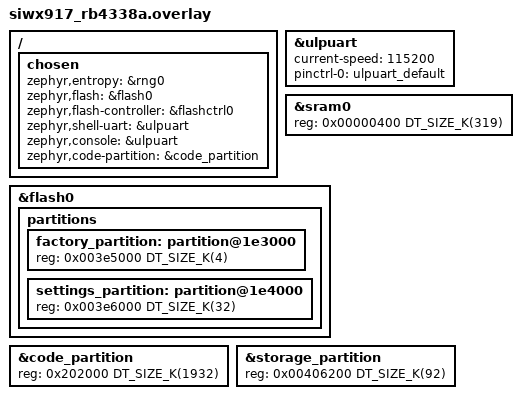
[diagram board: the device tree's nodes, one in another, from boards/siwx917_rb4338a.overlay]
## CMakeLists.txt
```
#
# Copyright (c) 2025 Project CHIP Authors
#
# Licensed under the Apache License, Version 2.0 (the "License");
# you may not use this file except in compliance with the License.
# You may obtain a copy of the License at
#
# http://www.apache.org/licenses/LICENSE-2.0
#
# Unless required by applicable law or agreed to in writing, software
# distributed under the License is distributed on an "AS IS" BASIS,
# WITHOUT WARRANTIES OR CONDITIONS OF ANY KIND, either express or implied.
# See the License for the specific language governing permissions and
# limitations under the License.
#
cmake_minimum_required(VERSION 3.20)

get_filename_component(CHIP_ROOT ${CMAKE_CURRENT_SOURCE_DIR}/../third_party/connectedhomeip REALPATH)
get_filename_component(GEN_DIR ${CHIP_ROOT}/zzz_generated/ REALPATH)
get_filename_component(ZEPHYR_PLATFORM_COMMON ${CHIP_ROOT}/examples/platform/silabs/zephyr REALPATH)
get_filename_component(SILABS_LIGHTING_COMMON ${CHIP_ROOT}/examples/lighting-app/silabs REALPATH)
get_filename_component(ALL_CLUSTERS_COMMON_DIR ${CHIP_ROOT}/examples/all-clusters-app/all-clusters-common REALPATH)


# Need this as wiseconnect abstraction is causing a build failure
add_definitions(-DMBEDTLS_X509_REMOVE_INFO )

list(APPEND ZEPHYR_EXTRA_MODULES ${CHIP_ROOT}/config/silabs)
find_package(Zephyr HINTS $ENV{ZEPHYR_BASE})

if(CONFIG_OPENTHREAD AND TARGET ot-config AND TARGET zephyr_interface)
    get_target_property(OT_CONFIG_DEFS ot-config INTERFACE_COMPILE_DEFINITIONS)
    if(OT_CONFIG_DEFS)
        list(FILTER OT_CONFIG_DEFS EXCLUDE REGEX "TARGET_PROPERTY:zephyr_interface,INTERFACE_COMPILE_DEFINITIONS")
    else()
        set(OT_CONFIG_DEFS "")
    endif()
    get_target_property(ZEPHYR_INTERFACE_DEFS zephyr_interface INTERFACE_COMPILE_DEFINITIONS)
    if(ZEPHYR_INTERFACE_DEFS)
        list(FILTER ZEPHYR_INTERFACE_DEFS EXCLUDE REGEX "COMPILE_LANGUAGE:CXX")
    else()
        set(ZEPHYR_INTERFACE_DEFS "")
    endif()
    set_target_properties(ot-config PROPERTIES
        INTERFACE_COMPILE_DEFINITIONS "${OT_CONFIG_DEFS};${ZEPHYR_INTERFACE_DEFS}")
endif()

if(CMAKE_C_COMPILER_ID STREQUAL "Clang")
    foreach(_mbedtls_lib mbedtls mbedx509 tfpsacrypto builtin p256-m pqcp extras platform utilities)
        if(TARGET ${_mbedtls_lib})
            target_compile_options(${_mbedtls_lib} PRIVATE -Wno-documentation -Wno-c99-extensions)
        endif()
    endforeach()
    
    if(CONFIG_OPENTHREAD)
        foreach(_ot_lib openthread-ftd openthread-mtd openthread-radio openthread-cli-ftd openthread-cli-mtd)
            if(TARGET ${_ot_lib})
                target_compile_options(${_ot_lib} PRIVATE -Wno-c99-extensions)
            endif()
        endforeach()
    endif()
endif()

# -Wmaybe-uninitialized has too many false positives, including on std::optional
# and chip::Optional.  Make it nonfatal.
#
# See https://gcc.gnu.org/bugzilla/show_bug.cgi?id=80635
target_compile_options(app PRIVATE -Werror -Wno-error=format)
if(CMAKE_C_COMPILER_ID STREQUAL "GNU")
    target_compile_options(app PRIVATE -Werror -Wno-error=maybe-uninitialized)
endif()

project(matter-zephyr-light)

include(${CHIP_ROOT}/config/silabs/app/enable-gnu-std.cmake)
include(${CHIP_ROOT}/src/app/chip_data_model.cmake)

target_include_directories(app
    PRIVATE
    include
    ${ZEPHYR_PLATFORM_COMMON}
)

target_sources(app
    PRIVATE
    src/AppTask.cpp
    src/DeviceCallbacks.cpp
    ../include/CHIPProjectConfig.h
    ${ZEPHYR_PLATFORM_COMMON}/main.cpp
    ${ZEPHYR_PLATFORM_COMMON}/AppTaskBase.cpp
    ${ZEPHYR_PLATFORM_COMMON}/AppTaskZephyr.cpp
    ${ZEPHYR_PLATFORM_COMMON}/CHIPDeviceManager.cpp
    ${ZEPHYR_PLATFORM_COMMON}/CommonDeviceCallbacks.cpp
    ${ZEPHYR_PLATFORM_COMMON}/DataModelCallbacks.cpp
)

if(CONFIG_CHIP_FACTORY_DATA)
    target_sources(app PRIVATE
                    ${CHIP_ROOT}/examples/platform/silabs/provision/ProvisionStorageReaderCommon.cpp
                    ${CHIP_ROOT}/examples/platform/silabs/provision/zephyr/ProvisionStorageReader.cpp
    )
    target_include_directories(app PRIVATE
                    ${CHIP_ROOT}/examples/platform/silabs
                    ${CHIP_ROOT}/third_party/silabs/matter_support/provision
    )
    target_compile_definitions(app PRIVATE
        SL_PROVISION_GENERATOR=0
    )
endif()

if(CONFIG_CHIP_OTA_REQUESTOR)
    target_sources(app PRIVATE
                    ${ZEPHYR_PLATFORM_COMMON}/ota_requestor/source/OTARequestorInitiatorCommon.cpp
                    ${ZEPHYR_PLATFORM_COMMON}/ota_requestor/source/OTARequestorInitiatorZephyr.cpp
    )
    target_include_directories(app PRIVATE
                    ${ZEPHYR_PLATFORM_COMMON}/ota_requestor/include/
    )
endif()

if(CONFIG_CHIP_WIFI)
  chip_configure_data_model(app INCLUDE_SERVER
      ZAP_FILE ${SILABS_LIGHTING_COMMON}/data_model/lighting-wifi-app.zap
  )
else()
  chip_configure_data_model(app INCLUDE_SERVER
      ZAP_FILE ${SILABS_LIGHTING_COMMON}/data_model/lighting-thread-app.zap
  )
endif()

if(CONFIG_CHIP_LIB_SHELL)
    target_compile_definitions(app PRIVATE ENABLE_CHIP_SHELL)
    target_include_directories(app PRIVATE 
                               ${CHIP_ROOT}/examples/shell/shell_common/include
                               ${ZEPHYR_PLATFORM_COMMON}/include
    )
    target_sources(app PRIVATE
                   ${ZEPHYR_PLATFORM_COMMON}/AppCLIZephyr.cpp
                   ${CHIP_ROOT}/examples/shell/shell_common/cmd_misc.cpp
                   ${CHIP_ROOT}/examples/shell/shell_common/cmd_otcli.cpp
                   ${CHIP_ROOT}/examples/shell/shell_common/cmd_server.cpp
    )
endif()

include(${CHIP_ROOT}/config/silabs/app/zephyr-post-build.cmake)
```

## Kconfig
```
#
#    Copyright (c) 2025 Project CHIP Authors
#
#    Licensed under the Apache License, Version 2.0 (the "License");
#    you may not use this file except in compliance with the License.
#    You may obtain a copy of the License at
#
#        http://www.apache.org/licenses/LICENSE-2.0
#
#    Unless required by applicable law or agreed to in writing, software
#    distributed under the License is distributed on an "AS IS" BASIS,
#    WITHOUT WARRANTIES OR CONDITIONS OF ANY KIND, either express or implied.
#    See the License for the specific language governing permissions and
#    limitations under the License.
#
mainmenu "Matter Silabs Lighting Example Application"

# Sample configuration used for Thread networking
if NET_L2_OPENTHREAD
choice OPENTHREAD_DEVICE_TYPE
	default OPENTHREAD_FTD
endchoice
endif # NET_L2_OPENTHREAD

rsource "../../../../config/silabs/Kconfig.defaults"
rsource "../../../../config/silabs/Kconfig"
source "Kconfig.zephyr"
```

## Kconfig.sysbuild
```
#
#    Copyright (c) 2026 Project CHIP Authors
#
#    Licensed under the Apache License, Version 2.0 (the "License");
#    you may not use this file except in compliance with the License.
#    You may obtain a copy of the License at
#
#        http://www.apache.org/licenses/LICENSE-2.0
#
#    Unless required by applicable law or agreed to in writing, software
#    distributed under the License is distributed on an "AS IS" BASIS,
#    WITHOUT WARRANTIES OR CONDITIONS OF ANY KIND, either express or implied.
#    See the License for the specific language governing permissions and
#    limitations under the License.
#

source "${ZEPHYR_BASE}/share/sysbuild/Kconfig"

# Silabs Matter OTA images use overwrite-only MCUboot

if BOOTLOADER_MCUBOOT

choice MCUBOOT_MODE
	default MCUBOOT_MODE_OVERWRITE_ONLY
endchoice

choice BOOT_SIGNATURE_TYPE
	default BOOT_SIGNATURE_TYPE_ECDSA_P256
endchoice

endif # BOOTLOADER_MCUBOOT
```

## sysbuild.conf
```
#
#    Copyright (c) 2026 Project CHIP Authors
#
#    Licensed under the Apache License, Version 2.0 (the "License");
#    you may not use this file except in compliance with the License.
#    You may obtain a copy of the License at
#
#        http://www.apache.org/licenses/LICENSE-2.0
#
#    Unless required by applicable law or agreed to in writing, software
#    distributed under the License is distributed on an "AS IS" BASIS,
#    WITHOUT WARRANTIES OR CONDITIONS OF ANY KIND, either express or implied.
#    See the License for the specific language governing permissions and
#    limitations under the License.
#

SB_CONFIG_MERGED_HEX_FILES=y

SB_CONFIG_MCUBOOT_MODE_OVERWRITE_ONLY=y
SB_CONFIG_BOOT_SIGNATURE_TYPE_ECDSA_P256=y
```

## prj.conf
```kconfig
#
#    Copyright (c) 2025 Project CHIP Authors
#
#    Licensed under the Apache License, Version 2.0 (the "License");
#    you may not use this file except in compliance with the License.
#    You may obtain a copy of the License at
#
#        http://www.apache.org/licenses/LICENSE-2.0
#
#    Unless required by applicable law or agreed to in writing, software
#    distributed under the License is distributed on an "AS IS" BASIS,
#    WITHOUT WARRANTIES OR CONDITIONS OF ANY KIND, either express or implied.
#    See the License for the specific language governing permissions and
#    limitations under the License.
#

# This sample uses Kconfig.defaults to set options common for all
# samples. This file should contain only options specific for this sample
# or overrides of default values.

# Main subsystems
CONFIG_CHIP=y
CONFIG_GPIO=y

# Chip related options
CONFIG_CHIP_PROJECT_CONFIG="../include/CHIPProjectConfig.h"
# 32773 == 0x8005 (example lighting-app)
CONFIG_CHIP_DEVICE_PRODUCT_ID=32773
CONFIG_CHIP_ENABLE_PAIRING_AUTOSTART=y
CONFIG_CHIP_BLE_EXT_ADVERTISING=y
CONFIG_CHIP_BLE_ADVERTISING_DURATION=60
CONFIG_BT_DEVICE_NAME="MatterLight"
CONFIG_NET_IF_MCAST_IPV6_ADDR_COUNT=5
CONFIG_SETTINGS_NVS_SECTOR_COUNT=6
CONFIG_STD_CPP17=y
# Workaround for undefined reference to `bt_rand'
CONFIG_BT_HOST_CRYPTO=y

CONFIG_LOG_MODE_MINIMAL=n
CONFIG_LOG_MODE_DEFERRED=y
CONFIG_LOG_BUFFER_SIZE=8192
CONFIG_LOG_DEFAULT_LEVEL=3

CONFIG_MBEDTLS_HEAP_SIZE=16384

# Shell commands
CONFIG_CHIP_LIB_SHELL=y

# Stack sizes
CONFIG_SYSTEM_WORKQUEUE_STACK_SIZE=4096
CONFIG_MAIN_STACK_SIZE=8192
CONFIG_SHELL_STACK_SIZE=4096
```

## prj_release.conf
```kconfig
#
#    Copyright (c) 2025 Project CHIP Authors
#
#    Licensed under the Apache License, Version 2.0 (the "License");
#    you may not use this file except in compliance with the License.
#    You may obtain a copy of the License at
#
#        http://www.apache.org/licenses/LICENSE-2.0
#
#    Unless required by applicable law or agreed to in writing, software
#    distributed under the License is distributed on an "AS IS" BASIS,
#    WITHOUT WARRANTIES OR CONDITIONS OF ANY KIND, either express or implied.
#    See the License for the specific language governing permissions and
#    limitations under the License.
#

# This sample uses Kconfig.defaults to set options common for all
# samples. This file should contain only options specific for this sample
# or overrides of default values.

# Enable CHIP
CONFIG_CHIP=y
CONFIG_CHIP_PROJECT_CONFIG="../include/CHIPProjectConfig.h"
# 32773 == 0x8005 (example lighting-app)
CONFIG_CHIP_DEVICE_PRODUCT_ID=32773
CONFIG_STD_CPP17=y

# Enable Matter pairing automatically on application start.
CONFIG_CHIP_ENABLE_PAIRING_AUTOSTART=y

# Enable Matter extended announcement and increase duration to 1 hour.
CONFIG_CHIP_BLE_EXT_ADVERTISING=y
CONFIG_CHIP_BLE_ADVERTISING_DURATION=60

# General networking settings
CONFIG_NET_IF_MCAST_IPV6_ADDR_COUNT=14

# Bluetooth Low Energy configuration
CONFIG_BT_DEVICE_NAME="MatterLight"

# Disable all debug features
CONFIG_USE_SEGGER_RTT=n
CONFIG_SHELL=n
CONFIG_OPENTHREAD_SHELL=n
CONFIG_CONSOLE=n
CONFIG_UART_CONSOLE=n
CONFIG_SERIAL=n
CONFIG_LOG=n
CONFIG_LOG_MODE_MINIMAL=n
CONFIG_ASSERT_VERBOSE=n
CONFIG_ASSERT_NO_FILE_INFO=y
CONFIG_PRINTK=n
CONFIG_PRINTK_SYNC=n
CONFIG_BOOT_BANNER=n
```

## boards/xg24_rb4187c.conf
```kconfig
#
#    Copyright (c) 2026 Project CHIP Authors
#    All rights reserved.
#
#    Licensed under the Apache License, Version 2.0 (the "License");
#    you may not use this file except in compliance with the License.
#    You may obtain a copy of the License at
#
#        http://www.apache.org/licenses/LICENSE-2.0
#
#    Unless required by applicable law or agreed to in writing, software
#    distributed under the License is distributed on an "AS IS" BASIS,
#    WITHOUT WARRANTIES OR CONDITIONS OF ANY KIND, either express or implied.
#    See the License for the specific language governing permissions and
#    limitations under the License.
#


# Drivers required to read/write the external SPI NOR;
# Enables external flash for OTA support
CONFIG_SPI=y
CONFIG_SPI_SILABS_EUSART=y
CONFIG_SPI_NOR=y

# Bootloader overwrite-only mode for computing image padding/overflow.
CONFIG_MCUBOOT_IMGTOOL_OVERWRITE_ONLY=y
CONFIG_MCUBOOT_BOOTLOADER_MODE_OVERWRITE_ONLY=y
```

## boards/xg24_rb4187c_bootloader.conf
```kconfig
#
#    Copyright (c) 2026 Project CHIP Authors
#    All rights reserved.
#
#    Licensed under the Apache License, Version 2.0 (the "License");
#    you may not use this file except in compliance with the License.
#    You may obtain a copy of the License at
#
#        http://www.apache.org/licenses/LICENSE-2.0
#
#    Unless required by applicable law or agreed to in writing, software
#    distributed under the License is distributed on an "AS IS" BASIS,
#    WITHOUT WARRANTIES OR CONDITIONS OF ANY KIND, either express or implied.
#    See the License for the specific language governing permissions and
#    limitations under the License.
#

# Overwrite-only install: the secondary slot (slot1) lives on the external SPI
# NOR and the primary (slot0) on internal flash, so the slots cannot be swapped
CONFIG_BOOT_UPGRADE_ONLY=y

# Drivers required to read/write the external SPI NOR;
# Enables external flash for OTA support
CONFIG_SPI=y
CONFIG_SPI_SILABS_EUSART=y
CONFIG_SPI_NOR=y
```

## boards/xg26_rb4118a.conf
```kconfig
#
#    Copyright (c) 2026 Project CHIP Authors
#    All rights reserved.
#
#    Licensed under the Apache License, Version 2.0 (the "License");
#    you may not use this file except in compliance with the License.
#    You may obtain a copy of the License at
#
#        http://www.apache.org/licenses/LICENSE-2.0
#
#    Unless required by applicable law or agreed to in writing, software
#    distributed under the License is distributed on an "AS IS" BASIS,
#    WITHOUT WARRANTIES OR CONDITIONS OF ANY KIND, either express or implied.
#    See the License for the specific language governing permissions and
#    limitations under the License.
#

# Bootloader overwrite-only mode for computing image padding/overflow.
CONFIG_MCUBOOT_IMGTOOL_OVERWRITE_ONLY=y
CONFIG_MCUBOOT_BOOTLOADER_MODE_OVERWRITE_ONLY=y
```

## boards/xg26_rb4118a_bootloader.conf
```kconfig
#
#    Copyright (c) 2026 Project CHIP Authors
#    All rights reserved.
#
#    Licensed under the Apache License, Version 2.0 (the "License");
#    you may not use this file except in compliance with the License.
#    You may obtain a copy of the License at
#
#        http://www.apache.org/licenses/LICENSE-2.0
#
#    Unless required by applicable law or agreed to in writing, software
#    distributed under the License is distributed on an "AS IS" BASIS,
#    WITHOUT WARRANTIES OR CONDITIONS OF ANY KIND, either express or implied.
#    See the License for the specific language governing permissions and
#    limitations under the License.
#

CONFIG_BOOT_UPGRADE_ONLY=y
```

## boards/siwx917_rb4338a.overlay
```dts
/*
 *    Copyright (c) 2025 Project CHIP Authors
 *    All rights reserved.
 *
 *    Licensed under the Apache License, Version 2.0 (the "License");
 *    you may not use this file except in compliance with the License.
 *    You may obtain a copy of the License at
 *
 *        http://www.apache.org/licenses/LICENSE-2.0
 *
 *    Unless required by applicable law or agreed to in writing, software
 *    distributed under the License is distributed on an "AS IS" BASIS
 *    WITHOUT WARRANTIES OR CONDITIONS OF ANY KIND, either express or implied.
 *    See the License for the specific language governing permissions and
 *    limitations under the License.
 */

/ {
	chosen {
		zephyr,entropy = &rng0;
		zephyr,flash = &flash0;
		zephyr,flash-controller = &flashctrl0;
		zephyr,shell-uart = &ulpuart;
		zephyr,console = &ulpuart;
		zephyr,code-partition = &code_partition;
	};
};

&ulpuart {
	status = "okay";
	current-speed = <115200>;
	pinctrl-0 = <&ulpuart_default>;
	pinctrl-names = "default";
};



&sram0 {
    status = "okay";
    reg = <0x00000400 DT_SIZE_K(319)>;
};

&flash0 {
        partitions {
                factory_partition: partition@1e3000 {
                        reg = <0x003e5000 DT_SIZE_K(4)>;
                };

                settings_partition: partition@1e4000 {
                        reg = <0x003e6000 DT_SIZE_K(32)>;
                };
        };
};

&code_partition {
       reg = <0x202000 DT_SIZE_K(1932)>;
};


&storage_partition {
        reg = <0x00406200 DT_SIZE_K(92)>;
};
```

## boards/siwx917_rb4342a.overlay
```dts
/*
 * Copyright (c) 2025 Project CHIP Authors
 *
 * Licensed under the Apache License, Version 2.0 (the "License");
 * you may not use this file except in compliance with the License.
 * You may obtain a copy of the License at
 *
 *     http://www.apache.org/licenses/LICENSE-2.0
 *
 * Unless required by applicable law or agreed to in writing, software
 * distributed under the License is distributed on an "AS IS" BASIS
 * WITHOUT WARRANTIES OR CONDITIONS OF ANY KIND, either express or implied.
 * See the License for the specific language governing permissions and
 * limitations under the License.
 */

&flash0 {
	partitions {
		/*
		 * M4 free space ends at 0x400000 (start of SoC ota_swap_partition).
		 * code (1912) + factory (4) + settings (32) + storage (92) = 2040 KiB.
		 * Do not place app NVM inside ota_swap — that region is owned by the
		 * NWP/Security Bootloader for RPS firmware upgrade.
		 */
		factory_partition: partition@3e0000 {
			reg = <0x003e0000 DT_SIZE_K(4)>;
		};

		settings_partition: partition@3e1000 {
			reg = <0x003e1000 DT_SIZE_K(32)>;
		};
	};
};

&code_partition {
	reg = <0x00202000 DT_SIZE_K(1912)>;
};

&storage_partition {
	reg = <0x003e9000 DT_SIZE_K(92)>;
};
```

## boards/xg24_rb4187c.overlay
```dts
/*
 *	Copyright (c) 2026 Project CHIP Authors
 *	All rights reserved.
 *
 *	Licensed under the Apache License, Version 2.0 (the "License");
 *	you may not use this file except in compliance with the License.
 *	You may obtain a copy of the License at
 *
 *	    http://www.apache.org/licenses/LICENSE-2.0
 *
 *	Unless required by applicable law or agreed to in writing, software
 *	distributed under the License is distributed on an "AS IS" BASIS
 *	WITHOUT WARRANTIES OR CONDITIONS OF ANY KIND, either express or implied.
 *	See the License for the specific language governing permissions and
 *	limitations under the License.
 */

/*
 * Internal flash (1536 KiB): boot (48) + slot0 (1024) + unused (416) + storage (48).
 * slot1 matches slot0 size on the external MX25R80.
 * slot0/slot1 must match for MCUboot in overwrite-only mode.
 */
/delete-node/ &slot0_partition;
/delete-node/ &slot1_partition;
/delete-node/ &storage_partition;

&flash0 {
	partitions {
		slot0_partition: partition@c000 {
			reg = <0x0000c000 DT_SIZE_K(1024)>;
			label = "image-0";
		};

		unused_partition: partition@10c000 {
			reg = <0x0010c000 DT_SIZE_K(416)>;
			label = "unused";
		};

		storage_partition: partition@174000 {
			reg = <0x00174000 DT_SIZE_K(48)>;
			label = "storage";
		};
	};
};

&mx25r80 {
	partitions {
		compatible = "fixed-partitions";
		#address-cells = <1>;
		#size-cells = <1>;

		slot1_partition: partition@0 {
			reg = <0x00000000 DT_SIZE_K(1024)>;
			label = "image-1";
		};
	};
};

&dma0 {
	status = "okay";
};

&usart0 {
	dmas = <&dma0 DMA_REQSEL_USART0TXBL>,
		   <&dma0 DMA_REQSEL_USART0RXDATAV>;
	dma-names = "tx", "rx";
};
```

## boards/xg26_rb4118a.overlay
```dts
/*
 *	Copyright (c) 2026 Project CHIP Authors
 *	All rights reserved.
 *
 *	Licensed under the Apache License, Version 2.0 (the "License");
 *	you may not use this file except in compliance with the License.
 *	You may obtain a copy of the License at
 *
 *		http://www.apache.org/licenses/LICENSE-2.0
 *
 *	Unless required by applicable law or agreed to in writing, software
 *	distributed under the License is distributed on an "AS IS" BASIS
 *	WITHOUT WARRANTIES OR CONDITIONS OF ANY KIND, either express or implied.
 *	See the License for the specific language governing permissions and
 *	limitations under the License.
 */

/*
 * Internal flash (3200 KiB): boot (48) + slot0 (1552) + slot1 (1552) + storage (48).
 */
/delete-node/ &slot0_partition;
/delete-node/ &slot1_partition;
/delete-node/ &storage_partition;

&flash0 {
	partitions {
		slot0_partition: partition@c000 {
			reg = <0x0000c000 DT_SIZE_K(1552)>;
			label = "image-0";
		};

		slot1_partition: partition@190000 {
			reg = <0x00190000 DT_SIZE_K(1552)>;
			label = "image-1";
		};

		storage_partition: partition@314000 {
			reg = <0x00314000 DT_SIZE_K(48)>;
			label = "storage";
		};
	};
};
```

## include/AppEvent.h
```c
/*
 *    Copyright (c) 2025 Project CHIP Authors
 *    All rights reserved.
 *
 *    Licensed under the Apache License, Version 2.0 (the "License");
 *    you may not use this file except in compliance with the License.
 *    You may obtain a copy of the License at
 *
 *        http://www.apache.org/licenses/LICENSE-2.0
 *
 *    Unless required by applicable law or agreed to in writing, software
 *    distributed under the License is distributed on an "AS IS" BASIS,
 *    WITHOUT WARRANTIES OR CONDITIONS OF ANY KIND, either express or implied.
 *    See the License for the specific language governing permissions and
 *    limitations under the License.
 */

#pragma once

struct AppEvent;
using EventHandler = void (*)(const AppEvent &);

struct AppEvent
{
    enum AppEventTypes
    {
        kEventType_Timer = 0,
        kEventType_TurnOn,
    };

    uint16_t Type;

    union
    {
        struct
        {
            void * Context;
        } TimerEvent;
        struct
        {
            uint8_t Action;
            int32_t Actor;
        } ClusterEvent;
    };

    EventHandler Handler;
};
```

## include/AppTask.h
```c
/*
 *
 *    Copyright (c) 2025 Project CHIP Authors
 *    All rights reserved.
 *
 *    Licensed under the Apache License, Version 2.0 (the "License");
 *    you may not use this file except in compliance with the License.
 *    You may obtain a copy of the License at
 *
 *        http://www.apache.org/licenses/LICENSE-2.0
 *
 *    Unless required by applicable law or agreed to in writing, software
 *    distributed under the License is distributed on an "AS IS" BASIS,
 *    WITHOUT WARRANTIES OR CONDITIONS OF ANY KIND, either express or implied.
 *    See the License for the specific language governing permissions and
 *    limitations under the License.
 */

#pragma once

#include "AppTaskZephyr.h"

class AppTask : public chip::Zephyr::App::AppTaskZephyr
{
public:
    ~AppTask() override{};
    void PreInitMatterStack(void) override;
    void PostInitMatterStack(void) override;
    void PostInitMatterServerInstance(void) override;
    // This returns an instance of this class.
    static AppTask & GetDefaultInstance();

private:
    static AppTask sAppTask;
};

/**
 * Returns the application-specific implementation of the AppTaskBase object.
 *
 * Applications can use this to gain access to features of the AppTaskBase
 * that are specific to the selected application.
 */
chip::Zephyr::App::AppTaskBase & GetAppTask();

/**
 * Set the state of LED1 to reflect the on/off state.
 * This is a no-op if LED1 is not available on the board.
 *
 * @param state true to turn the LED on, false to turn it off.
 */
void SetLightState(bool state);
```

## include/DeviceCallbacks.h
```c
/*
 *
 *    Copyright (c) 2026 Project CHIP Authors
 *    All rights reserved.
 *
 *    Licensed under the Apache License, Version 2.0 (the "License");
 *    you may not use this file except in compliance with the License.
 *    You may obtain a copy of the License at
 *
 *        http://www.apache.org/licenses/LICENSE-2.0
 *
 *    Unless required by applicable law or agreed to in writing, software
 *    distributed under the License is distributed on an "AS IS" BASIS,
 *    WITHOUT WARRANTIES OR CONDITIONS OF ANY KIND, either express or implied.
 *    See the License for the specific language governing permissions and
 *    limitations under the License.
 */

/**
 * @file DeviceCallbacks.h
 *
 * Lighting app implementation for the DeviceManager callbacks for all applications
 *
 **/

#pragma once

#include "CHIPDeviceManager.h"
#include "CommonDeviceCallbacks.h"

namespace LightingApp {

class DeviceCallbacks : public chip::Zephyr::App::CommonDeviceCallbacks
{
public:
    void PostAttributeChangeCallback(chip::EndpointId endpoint, chip::ClusterId clusterId, chip::AttributeId attributeId,
                                     uint8_t type, uint16_t size, uint8_t * value) override;
};

} // namespace LightingApp

namespace chip::Zephyr::App {
/**
 * Returns the application-specific implementation of the CommonDeviceCallbacks object.
 *
 * Applications can use this to gain access to features of the CommonDeviceCallbacks
 * that are specific to the selected application.
 */
chip::DeviceManager::CHIPDeviceManagerCallbacks & GetDeviceCallbacks();

} // namespace chip::Zephyr::App
```

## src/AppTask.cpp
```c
/*
 *
 *    Copyright (c) 2025 Project CHIP Authors
 *    All rights reserved.
 *
 *    Licensed under the Apache License, Version 2.0 (the "License");
 *    you may not use this file except in compliance with the License.
 *    You may obtain a copy of the License at
 *
 *        http://www.apache.org/licenses/LICENSE-2.0
 *
 *    Unless required by applicable law or agreed to in writing, software
 *    distributed under the License is distributed on an "AS IS" BASIS,
 *    WITHOUT WARRANTIES OR CONDITIONS OF ANY KIND, either express or implied.
 *    See the License for the specific language governing permissions and
 *    limitations under the License.
 */

#include "AppTask.h"
#include "CHIPDeviceManager.h"

#include <app-common/zap-generated/ids/Attributes.h>
#include <app-common/zap-generated/ids/Clusters.h>
#include <app/clusters/on-off-server/on-off-server.h>
#include <app/server/Server.h>
#include <app/util/attribute-storage.h>
#include <platform/CHIPDeviceLayer.h>

#include <zephyr/drivers/gpio.h>
#include <zephyr/kernel.h>
#include <zephyr/logging/log.h>

#ifdef MATTER_DM_PLUGIN_BINDING
#include "binding-handler.h"
#endif

LOG_MODULE_DECLARE(app, CONFIG_CHIP_APP_LOG_LEVEL);

using namespace chip;
using namespace chip::DeviceLayer;
using namespace chip::app::Clusters;

namespace {
constexpr EndpointId kLightEndpointId = 1;
} // namespace

/* -------------------------------------------------------------------------- */
/*                          LED devicetree bindings                           */
/* -------------------------------------------------------------------------- */

#if DT_NODE_EXISTS(DT_ALIAS(led0))
#define HAS_LED0 1
static const struct gpio_dt_spec sLed0 = GPIO_DT_SPEC_GET(DT_ALIAS(led0), gpios);
static struct k_timer sLed0BlinkTimer;
static bool sLed0State;
#endif

#if DT_NODE_EXISTS(DT_ALIAS(led1))
#define HAS_LED1 1
static const struct gpio_dt_spec sLed1 = GPIO_DT_SPEC_GET(DT_ALIAS(led1), gpios);
#endif

/* -------------------------------------------------------------------------- */
/*                        Button devicetree bindings                          */
/* -------------------------------------------------------------------------- */

#if DT_NODE_EXISTS(DT_ALIAS(sw0))
#define HAS_BUTTON0 1
static const struct gpio_dt_spec sButton0 = GPIO_DT_SPEC_GET(DT_ALIAS(sw0), gpios);
static struct gpio_callback sButton0CbData;
static struct k_work_delayable sFactoryResetWarningWork;
static struct k_work_delayable sFactoryResetTriggerWork;
#endif

#if DT_NODE_EXISTS(DT_ALIAS(sw1))
#define HAS_BUTTON1 1
static const struct gpio_dt_spec sButton1 = GPIO_DT_SPEC_GET(DT_ALIAS(sw1), gpios);
static struct gpio_callback sButton1CbData;
static struct k_work sToggleOnOffWork;
#endif

/* -------------------------------------------------------------------------- */
/*                           LED helper functions                             */
/* -------------------------------------------------------------------------- */

#ifdef HAS_LED0
static void Led0BlinkTimerHandler(struct k_timer * timer)
{
    sLed0State = !sLed0State;
    gpio_pin_set_dt(&sLed0, static_cast<int>(sLed0State));
}
#endif

/* -------------------------------------------------------------------------- */
/*                             Button callbacks                               */
/* -------------------------------------------------------------------------- */

#ifdef HAS_BUTTON0
static void FactoryResetWarningWorkHandler(struct k_work * work)
{
    LOG_INF("Keep holding to factory reset in 3 seconds. Release to cancel.");
}

static void FactoryResetTriggerWorkHandler(struct k_work * work)
{
    LOG_INF("Factory reset triggered");
    chip::Server::GetInstance().ScheduleFactoryReset();
}

static void Button0PressedHandler(const struct device * dev, struct gpio_callback * cb, uint32_t pins)
{
    if (gpio_pin_get_dt(&sButton0) > 0)
    {
        k_work_schedule(&sFactoryResetWarningWork, K_SECONDS(2));
        k_work_schedule(&sFactoryResetTriggerWork, K_SECONDS(5));
    }
    else
    {
        bool wasPending = k_work_cancel_delayable(&sFactoryResetTriggerWork) != 0;
        k_work_cancel_delayable(&sFactoryResetWarningWork);
        if (wasPending)
        {
            LOG_INF("Factory reset canceled");
        }
    }
}
#endif

#ifdef HAS_BUTTON1
static void ToggleOnOffCluster(intptr_t arg)
{
    bool currentValue;
    static_cast<void>(arg);
    OnOffServer::Instance().getOnOffValue(kLightEndpointId, &currentValue);
    OnOffServer::Instance().setOnOffValue(kLightEndpointId, !currentValue, false);
}

static void ToggleOnOffWorkHandler(struct k_work * work)
{
    static_cast<void>(work);
    RETURN_SAFELY_IGNORED PlatformMgr().ScheduleWork(ToggleOnOffCluster, 0);
}

static void Button1PressedHandler(const struct device * dev, struct gpio_callback * cb, uint32_t pins)
{
    k_work_submit(&sToggleOnOffWork);
}
#endif

/* -------------------------------------------------------------------------- */
/*                          AppTask implementation                            */
/* -------------------------------------------------------------------------- */

void AppTask::PreInitMatterStack()
{
    ChipLogProgress(DeviceLayer, "Welcome to Zephyr Matter Light Demo App");

#ifdef HAS_LED0
    if (gpio_is_ready_dt(&sLed0))
    {
        VerifyOrDie(gpio_pin_configure_dt(&sLed0, GPIO_OUTPUT_INACTIVE) == 0);
        k_timer_init(&sLed0BlinkTimer, Led0BlinkTimerHandler, nullptr);
    }
#endif

#ifdef HAS_LED1
    if (gpio_is_ready_dt(&sLed1))
    {
        VerifyOrDie(gpio_pin_configure_dt(&sLed1, GPIO_OUTPUT_INACTIVE) == 0);
    }
#endif

#ifdef HAS_BUTTON0
    k_work_init_delayable(&sFactoryResetWarningWork, FactoryResetWarningWorkHandler);
    k_work_init_delayable(&sFactoryResetTriggerWork, FactoryResetTriggerWorkHandler);

    if (gpio_is_ready_dt(&sButton0))
    {
        VerifyOrDie(gpio_pin_configure_dt(&sButton0, GPIO_INPUT) == 0);
        VerifyOrDie(gpio_pin_interrupt_configure_dt(&sButton0, GPIO_INT_EDGE_BOTH) == 0);
        gpio_init_callback(&sButton0CbData, Button0PressedHandler, BIT(sButton0.pin));
        gpio_add_callback(sButton0.port, &sButton0CbData);
    }
#endif

#ifdef HAS_BUTTON1
    k_work_init(&sToggleOnOffWork, ToggleOnOffWorkHandler);

    if (gpio_is_ready_dt(&sButton1))
    {
        VerifyOrDie(gpio_pin_configure_dt(&sButton1, GPIO_INPUT) == 0);
        VerifyOrDie(gpio_pin_interrupt_configure_dt(&sButton1, GPIO_INT_EDGE_TO_ACTIVE) == 0);
        gpio_init_callback(&sButton1CbData, Button1PressedHandler, BIT(sButton1.pin));
        gpio_add_callback(sButton1.port, &sButton1CbData);
    }
#endif
}

void AppTask::PostInitMatterStack()
{
#ifdef MATTER_DM_PLUGIN_BINDING
    CHIP_ERROR err = InitBindingHandlers();
    if (err != CHIP_NO_ERROR)
    {
        ChipLogError(DeviceLayer, "InitBindingHandlers failed: %" CHIP_ERROR_FORMAT, err.Format());
    }
#endif

#ifdef HAS_LED0
    if (ConnectivityMgr().IsBLEAdvertisingEnabled())
    {
        sLed0State = false;
        k_timer_start(&sLed0BlinkTimer, K_MSEC(500), K_MSEC(500));
    }
#endif
}

void AppTask::PostInitMatterServerInstance() {}

AppTask & AppTask::GetDefaultInstance()
{
    static AppTask sAppTask;
    return sAppTask;
}

chip::Zephyr::App::AppTaskBase & chip::Zephyr::App::GetAppTask()
{
    return AppTask::GetDefaultInstance();
}

void SetLightState(bool state)
{
#ifdef HAS_LED1
    gpio_pin_set_dt(&sLed1, static_cast<int>(state));
#else
    (void) state;
#endif
}
```

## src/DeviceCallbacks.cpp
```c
/*
 *
 *    Copyright (c) 2026 Project CHIP Authors
 *    All rights reserved.
 *
 *    Licensed under the Apache License, Version 2.0 (the "License");
 *    you may not use this file except in compliance with the License.
 *    You may obtain a copy of the License at
 *
 *        http://www.apache.org/licenses/LICENSE-2.0
 *
 *    Unless required by applicable law or agreed to in writing, software
 *    distributed under the License is distributed on an "AS IS" BASIS,
 *    WITHOUT WARRANTIES OR CONDITIONS OF ANY KIND, either express or implied.
 *    See the License for the specific language governing permissions and
 *    limitations under the License.
 */

#include <lib/support/logging/CHIPLogging.h>

#include "AppTask.h"
#include "DeviceCallbacks.h"
#if CONFIG_ENABLE_FEEDBACK
#include "UserInterfaceFeedback.h"
#endif

#include <app-common/zap-generated/ids/Attributes.h>
#include <app-common/zap-generated/ids/Clusters.h>

using namespace ::chip;
using namespace ::chip::app::Clusters;

void LightingApp::DeviceCallbacks::PostAttributeChangeCallback(chip::EndpointId endpoint, chip::ClusterId clusterId,
                                                               chip::AttributeId attributeId, uint8_t type, uint16_t size,
                                                               uint8_t * value)
{
    if (clusterId == OnOff::Id)
    {
        if (attributeId != OnOff::Attributes::OnOff::Id)
        {
            ChipLogProgress(Zcl, "Unknown attribute ID: " ChipLogFormatMEI, ChipLogValueMEI(attributeId));
            return;
        }
        if (value != nullptr)
        {
            SetLightState(*value != 0);
        }
    }
    else if (clusterId == LevelControl::Id)
    {
        if (attributeId != LevelControl::Attributes::CurrentLevel::Id)
        {
            ChipLogProgress(Zcl, "Unknown attribute ID: " ChipLogFormatMEI, ChipLogValueMEI(attributeId));
            return;
        }
#if LIGHTING_MANAGER_ENABLE_DIMMABLE_LED
        if (*value > 1 && *value < 254)
        {
            ChipLogProgress(Zcl, "Setting value: %d", *value);
            // The cluster attribute value will be read in RestoreState and the proper action will be taken: e.g. ApplyDim.
#if CONFIG_ENABLE_FEEDBACK
            FeedbackMgr().RestoreState();
#endif
        }
#endif
    }
    else if (clusterId == ColorControl::Id)
    {
        ChipLogProgress(Zcl, "Color Control attribute ID: " ChipLogFormatMEI " Type: %u Value: %u, length %u",
                        ChipLogValueMEI(attributeId), type, *value, size);

        // WIP Apply attribute change to Light
    }
    else
    {
        ChipLogProgress(Zcl, "Unknown cluster ID: " ChipLogFormatMEI, ChipLogValueMEI(clusterId));
    }
}

chip::DeviceManager::CHIPDeviceManagerCallbacks & chip::Zephyr::App::GetDeviceCallbacks()
{
    static LightingApp::DeviceCallbacks sDeviceCallbacks;
    return sDeviceCallbacks;
}
```
